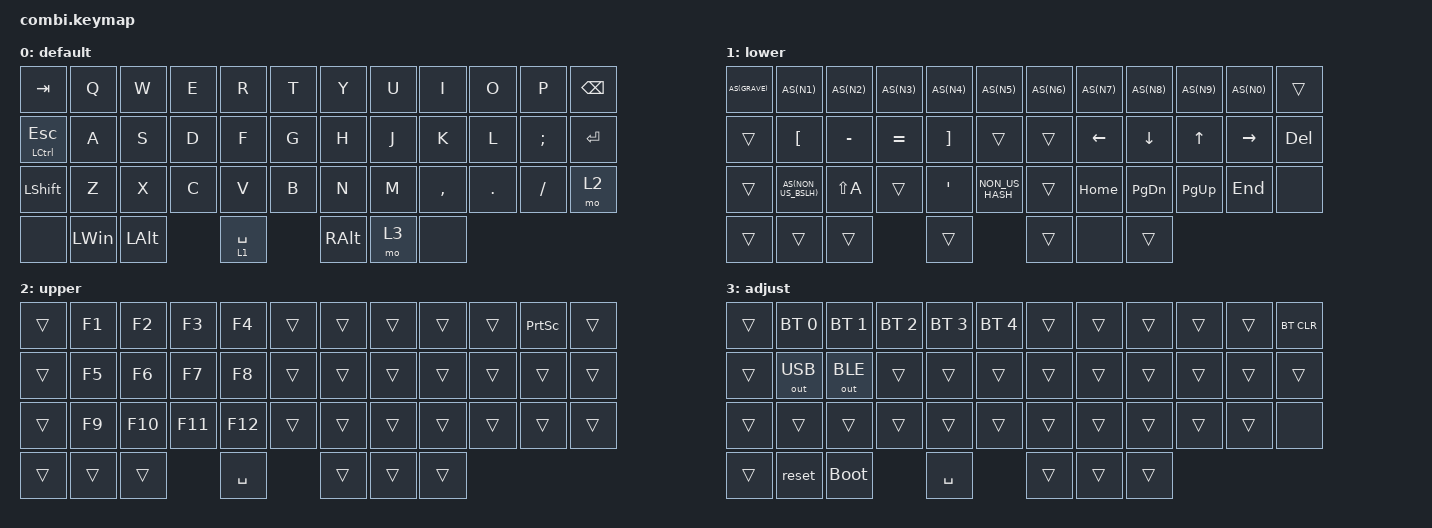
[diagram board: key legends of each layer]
#include <behaviors.dtsi>
#include <dt-bindings/zmk/keys.h>
#include <dt-bindings/zmk/bt.h>
#include <dt-bindings/zmk/outputs.h>
#include <dt-bindings/zmk/ext_power.h>

&lt {
  flavor = "balanced";
};

#define AS(keycode) &as LS(keycode) keycode

/ {
	behaviors {
            as: auto_shift {
                compatible = "zmk,behavior-hold-tap";
                label = "AUTO_SHIFT";
                #binding-cells = <2>;
                tapping_term_ms = <175>;
                quick_tap_ms = <0>;
                flavor = "tap-preferred";
                bindings = <&kp>, <&kp>;
            };
        };
    
    keymap {
		compatible = "zmk,keymap";

		default {

// -------------------------------------------------------------------------------
// | TAB  |  Q  |  W  |  E  |  R  |  T  |  Y  |  U  |  I  |  O  |  P  |  BKSPC   |
// | LCTL  |  A  |  S  |  D  |  F  |  G  |  H  |  J  |  K  |  L  |  ;  |  ENTER  |
// |  SHIFT  |  Z  |  X  |  C  |  V  |  B  |  N  |  M  |  ,   |  .   |  ^  |  /  |
// |       |  WIN   |  ALT  |            SPACE               |  <-  |  v  |      |
// -------------------------------------------------------------------------------
			bindings = <
			
                &kp TAB &kp Q &kp W &kp E &kp R &kp T &kp Y &kp U &kp I &kp O &kp P &kp BSPC
                &mt LCTRL ESC &kp A &kp S &kp D &kp F &kp G &kp H &kp J &kp K &kp L &kp SEMI &kp RET
                &kp LSHFT &kp Z &kp X &kp C &kp V &kp B &kp N &kp M &kp COMMA &kp DOT &kp SLASH &mo 2
                &none &kp LWIN &kp LALT &lt 1 SPACE &kp RALT &mo 3 &none 
			>;
		};

		lower {
            bindings = <
                AS(GRAVE) AS(N1) AS(N2) AS(N3) AS(N4) AS(N5) AS(N6) AS(N7) AS(N8) AS(N9) AS(N0) &trans
                &trans &kp LBKT &kp MINUS &kp EQUAL &kp RBKT &trans &trans &kp LEFT &kp DOWN &kp UP &kp RIGHT &kp DEL
                &trans AS(NON_US_BSLH) &kp LS(A) &trans &kp SQT &kp NON_US_HASH &trans &kp HOME &kp PG_DN &kp PG_UP &kp END &none
                &trans &trans &trans &trans &trans &none &trans
            >;
        };

		upper {
            bindings = <
                &trans  &kp F1  &kp F2  &kp F3  &kp F4  &trans  &trans  &trans  &trans  &trans  &kp PSCRN  &trans
                &trans  &kp F5  &kp F6  &kp F7  &kp F8  &trans  &trans  &trans  &trans  &trans  &trans  &trans
                &trans  &kp F9  &kp F10 &kp F11 &kp F12 &trans  &trans  &trans  &trans  &trans  &trans  &trans
                &trans  &trans  &trans                 &kp SPACE                   &trans  &trans  &trans
            >;
        };

		adjust {
            bindings = <
                &trans   &bt BT_SEL 0   &bt BT_SEL 1    &bt BT_SEL 2    &bt BT_SEL 3    &bt BT_SEL 4    &trans          &trans          &trans          &trans          &trans          &bt BT_CLR
                &trans  &out OUT_USB    &out OUT_BLE    &trans          &trans          &trans          &trans          &trans          &trans          &trans          &trans          &trans
                &trans  &trans          &trans          &trans          &trans          &trans          &trans          &trans          &trans          &trans          &trans          &none
                &trans  &reset          &bootloader                                              &kp SPACE                                               &trans  &trans  &trans
            >;
        };

	};
};
